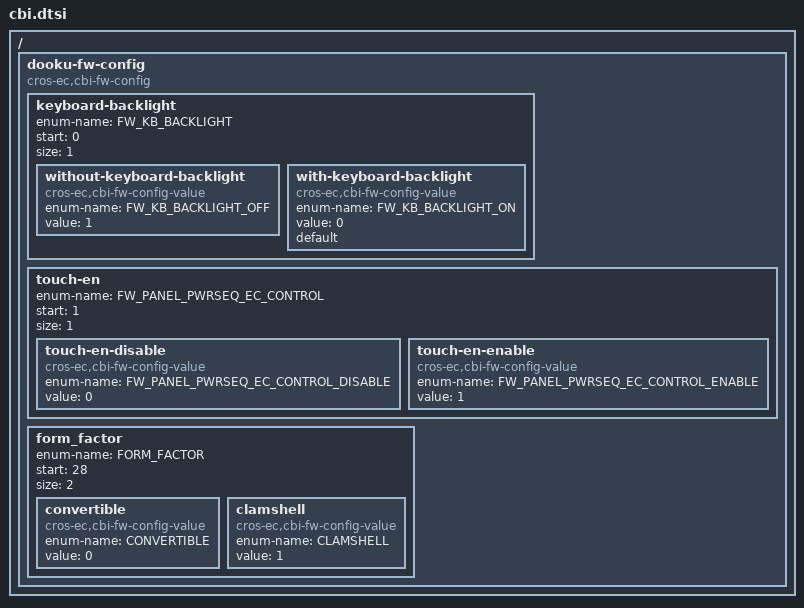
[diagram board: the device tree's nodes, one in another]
/* Copyright 2025 The ChromiumOS Authors
 * Use of this source code is governed by a BSD-style license that can be
 * found in the LICENSE file.
 */

/ {
	dooku-fw-config {
		compatible = "cros-ec,cbi-fw-config";

		/*
		 * FW_CONFIG field to indicate which keyboard layout
		 * should be used.
		 */
		keyboard-backlight {
			enum-name = "FW_KB_BACKLIGHT";
			start = <0>;
			size = <1>;

			without-keyboard-backlight {
				compatible = "cros-ec,cbi-fw-config-value";
				enum-name = "FW_KB_BACKLIGHT_OFF";
				value = <1>;
			};
			with-keyboard-backlight {
				compatible = "cros-ec,cbi-fw-config-value";
				enum-name = "FW_KB_BACKLIGHT_ON";
				value = <0>;
				default;
			};
		};
		/*
		 * FW_CONFIG field to enable touch panel power sequence
		 * control or not.
		 */
		touch-en {
			enum-name = "FW_PANEL_PWRSEQ_EC_CONTROL";
			start = <1>;
			size = <1>;

			touch-en-disable {
				compatible = "cros-ec,cbi-fw-config-value";
				enum-name = "FW_PANEL_PWRSEQ_EC_CONTROL_DISABLE";
				value = <0>;
			};
			touch-en-enable {
				compatible = "cros-ec,cbi-fw-config-value";
				enum-name = "FW_PANEL_PWRSEQ_EC_CONTROL_ENABLE";
				value = <1>;
			};
		};
		/*
		 * FW_CONFIG field to describe Clamshell/Convertible.
		 */
		form_factor {
			enum-name = "FORM_FACTOR";
			start = <28>;
			size = <2>;

			/*
			 * 0: convertible, 1: clamshell
			 */
			convertible {
				compatible = "cros-ec,cbi-fw-config-value";
				enum-name = "CONVERTIBLE";
				value = <0>;
			};
			clamshell {
				compatible = "cros-ec,cbi-fw-config-value";
				enum-name = "CLAMSHELL";
				value = <1>;
			};
		};
	};
};
